# ETAP register map
Vendor: Texas Instruments
Peripheral module from a debugger description file (folder msp).
Registers are 64-bit, read-only, reset 0x0 unless marked. A register's access mark holds for its fields unless they carry their own. Offsets are as the file gives them; lines under a group give offsets from that group; [hi:lo] are bit positions; {n}, {i} and the like mark numbered series; 'fields as' and 'values as' point back to an identical list; <NAME> marks a mode.

## Hidden — JSTATE decoding
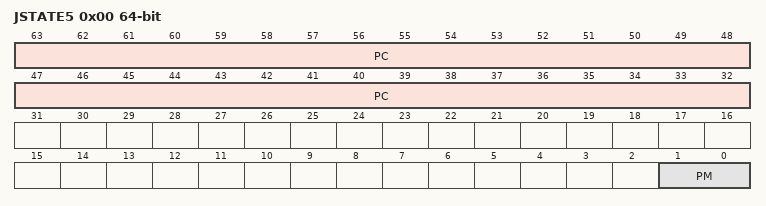
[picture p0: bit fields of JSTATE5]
0x00 JSTATE5 — Digital JTAG State Register
  [63:32] PC
  [1:0] PM — %LEGO_PM
    0=ACTIVE; 1=SLEEP; 2=STOP; 3=STANDBY
